# cslr_mmcsdc5509_001 register map
Vendor: Texas Instruments
Peripheral module from a debugger description file.
Registers are 16-bit, read-write, reset 0x0 unless marked. A register's access mark holds for its fields unless they carry their own. Offsets are as the file gives them; lines under a group give offsets from that group; [hi:lo] are bit positions; {n}, {i} and the like mark numbered series; 'fields as' and 'values as' point back to an identical list; <NAME> marks a mode.

## MMCSD — MultiMediaCard / SD Card Controller
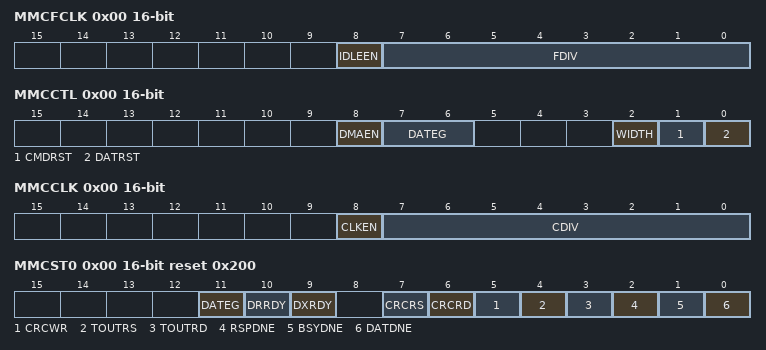
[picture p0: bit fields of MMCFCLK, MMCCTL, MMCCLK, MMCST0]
0x00 MMCFCLK access per field (reset mask 0xFF00) — Function Clock Control Register
  [8] IDLEEN rw — IDLE enable
    0=The function clock cannot be stopped by an IDLE instruction; 1=If an IDLE instruction makes the peripherals domain idle, the MMC controller is idle (the function clock is stopped)
  [7:0] FDIV rw — Use this field to set the divide-down value for the function clock.
0x00 MMCCTL access per field — MMC Control Register
  [8] DMAEN rw — DMA event enable
    0=Disable DMA events; 1=Enable DMA events
  [7:6] DATEG rw — DAT3 edge detection select
    0=DAT3 edge detection is disabled; 1=DAT3 rising edge detection is enabled; 2=DAT3 falling edge detection is enabled; 3=DAT3 dual edge detection is enabled (both edges detected)
  [2] WIDTH rw — Data bus width select
    0=The data bus has 1 bit (DAT0 is used); 1=The data bus has 4 bits (DAT0−3 are used)
  [1] CMDRST rw — CMD (command) logic reset
    0=The CMD logic of the MMC controller is enabled; 1=The CMD logic of the MMC controller is in the reset state
  [0] DATRST rw — DAT (data) logic reset
    0=The DAT logic of the MMC controller is enabled; 1=The DAT logic of the MMC controller is in the reset state
0x00 MMCCLK access per field (reset mask 0xFF00) — Clock Control Register
  [8] CLKEN rw — CLK pin enable
    0=The CLK pin is disabled and fixed low; 1=The CLK pin is enabled; it shows the memory clock signal
  [7:0] CDIV rw — Use this field to set the divide-down value for the memory clock.
0x00 MMCST0 ro reset 0x200 — Status Register 0
  [11] DATEG — DAT3 edge detected
    0=A DAT3 edge has not been detected; 1=A DAT3 edge has been detected
  [10] DRRDY — Data receive ready
    0=MMCDRR is not ready; 1=MMCDRR is ready
  [9] DXRDY — Data transmit ready
    0=MMCDXR is not ready; 1=MMCDXR is ready
  [7] CRCRS — Response CRC error
    0=A response CRC error has not been detected; 1=A response CRC error has been detected
  [6] CRCRD — Read-data CRC error
    0=A read-data CRC error has not been detected; 1=A read-data CRC error has been detected
  [5] CRCWR — Write-data CRC error
    0=A write-data CRC error has not been detected; 1=A write-data CRC error has been detected
  [4] TOUTRS — Response time-out event
    0=A response time-out event has not occurred; 1=A time-out event has occurred while the MMC controller was waiting for a response to a command
  [3] TOUTRD — Read-data time-out event
    0=A read-data time-out event has not occurred; 1=A time-out event has occurred while the MMC controller was waiting for data
  [2] RSPDNE — Command/response done
    0=The response has not been fully received with no CRC error; 1=The response has been fully received with no CRC error
  [1] BSYDNE — Busy done
    0=The memory card is busy; 1=The memory card is no longer sending a busy signal
  [0] DATDNE — Data transfer done
    0=The data has not been fully received with no CRC error; 1=The data has been fully received with no CRC error; 0=The data has not been fully transmitted; 1=The data has been fully transmitted
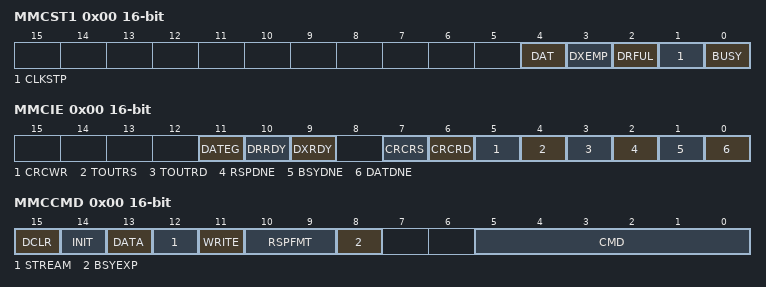
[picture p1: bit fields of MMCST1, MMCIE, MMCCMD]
0x00 MMCST1 ro — Status Register 1
  [4] DAT — DAT3 level
    0=The signal level on the DAT3 pin is low; 1=The signal level on the DAT3 pin is high
  [3] DXEMP — Data transmit empty
    0=A data transmit empty condition has not been detected; 1=A data transmit empty condition has been detected
  [2] DRFUL — Data receive full
    0=A data receive full condition has not been detected; 1=A data receive full condition has been detected
  [1] CLKSTP — Clock stopped
    0=The CLK pin is active; 1=The CLK pin is held low
  [0] BUSY
    0=A busy signal has not been detected; 1=A busy signal has been detected (the memory card is busy)
0x00 MMCIE access per field — Interrupt Enable Register
  [11] DATEG rw — DAT3 edge interrupt enable
    0=The DAT3 edge detect interrupt is disabled; 1=The DAT3 edge detect interrupt is enabled
  [10] DRRDY rw — Data receive ready interrupt enable
    0=The data receive ready interrupt is disabled; 1=The data receive ready interrupt is enabled
  [9] DXRDY rw — Data transmit ready interrupt enable
    0=The data transmit ready interrupt is disabled; 1=The data transmit ready interrupt is enabled
  [7] CRCRS rw — Response CRC error interrupt enable
    0=The response CRC error interrupt is disabled; 1=The response CRC error interrupt is enabled
  [6] CRCRD rw — Read-data CRC error interrupt enable
    0=The read-data CRC error interrupt is disabled; 1=The read-data CRC error interrupt is enabled
  [5] CRCWR rw — Write-data CRC error interrupt enable
    0=The write-data CRC error interrupt is disabled; 1=The write-data CRC error interrupt is enabled
  [4] TOUTRS rw — Response time-out interrupt enable
    0=The response time-out interrupt is disabled; 1=The response time-out interrupt is enabled
  [3] TOUTRD rw — Read-data time-out interrupt enable
    0=The read-data time-out interrupt is disabled; 1=The read-data time-out interrupt is enabled
  [2] RSPDNE rw — Response/command done interrupt enable
    0=The response/command done interrupt is disabled; 1=The response/command done interrupt is enabled
  [1] BSYDNE rw — Busy done interrupt enable
    0=The busy done interrupt is disabled; 1=The busy done interrupt is enabled
  [0] DATDNE rw — Data transfer done interrupt enable
    0=The data transfer done interrupt is disabled; 1=The data transfer done interrupt is enabled
0x00 MMCTOR access per field — Response Time-Out Register
  [7:0] TOR rw — Time-out period for response
    0=No time-out
0x00 MMCTOD — Data Read Time-Out Register
  [15:0] TOD — Time-out period for data read
    0=No time-out
0x00 MMCBLEN access per field (reset mask 0xF000) — Block Length Register
  [11:0] BLEN rw — Use this field to set the block length, which is the byte count of a data block.
0x00 MMCNBLK — Number of Blocks Register
  [15:0] NBLK — Use this field to set the total number of blocks to be transferred.
    0=Infinite number of blocks
0x00 MMCNBLC ro — Number of Blocks Counter Register
  [15:0] NBLC — Read this field to determine the number of blocks left to be transferred.
0x00 MMCDRR — Data Receive Register
  [15:0] DRR — This field holds data received by the MMC controller.
0x00 MMCDXR — Data Transmit Register
  [15:0] DXR — Data to be transmitted by the MMC controller must be written to this field.
0x00 MMCCMD access per field — Command Register
  [15] DCLR rw — Data receive/transmit clear.
    0=Do not clear DRRDY and DXRDY; 1=Clear DRRDY and DXRDY
  [14] INIT rw — Initialization clock cycles
    0=Do not insert initialization clock cycles; 1=Insert initialization clock cycles
  [13] DATA rw — Data transfer indicator
    0=There is to be no data transfer; 1=There is a data transfer associated with the command
  [12] STREAM rw — Stream enable
    0=If DATA = 1, the data transfer is a block transfer; 1=If DATA = 1, the data transfer is a stream transfer
  [11] WRITE rw — Write enable
    0=If DATA = 1, the data transfer is a read operation; 1=If DATA = 1, the data transfer is a write operation
  [10:9] RSPFMT rw — Response format (expected type of response to the command)
    0=No response; 1=R1, R4, R5, or R6. 48 bits with CRC.; 2=R2. 136 bits with CRC.; 3=R3. 48 bits with no CRC.
  [8] BSYEXP rw — Busy expected.
    0=A busy signal is not expected; 1=A busy signal is expected
  [5:0] CMD rw — Command index.
0x00 MMCARGH — Argument Register, High
  [15:0] ARGH — High part (upper 16 bits) of argument
0x00 MMCARGL — Argument Register, Low
  [15:0] ARGL — Low part (lower 16 bits) of argument
0x00 MMCRSP{i} (i=0..7) — Response Registers
  [15:0] RSP — When the MMC controller receives a response, it is stored in some or all of the eight response registers (MMCRSP7−MMCRSP0).
0x00 MMCDRSP access per field — Data Response Register
  [7:0] DRSP rw — During a write operation the CRC status token is stored in this register.
0x00 MMCCIDX access per field — Command Index Register
  [7:0] CIDX rw — When a command index byte is received, the byte is stored in this field.
